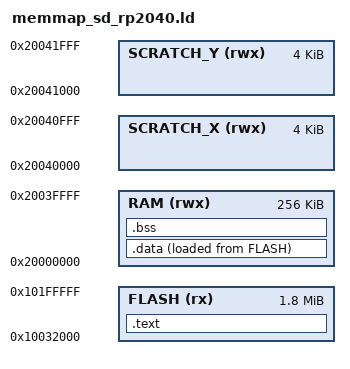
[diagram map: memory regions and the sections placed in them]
MEMORY
{
    FLASH(rx) : ORIGIN = 0x10000000 + 200k, LENGTH = 2048k - 200k
    RAM(rwx) : ORIGIN = 0x20000000, LENGTH = 256k
    SCRATCH_X(rwx) : ORIGIN = 0x20040000, LENGTH = 4k
    SCRATCH_Y(rwx) : ORIGIN = 0x20041000, LENGTH = 4k
}

ENTRY(bare_reset)

SECTIONS
{
    .text : {
        __text_start = .;
        KEEP(*(.vectors))
        *(.text*)
        *(.rodata*)
        . = ALIGN(4);
        __text_end = .;
    } > FLASH

    .data : {
        . = ALIGN(4);
        __data_start = .;
        *(.data*)
        . = ALIGN(4);
        __data_end = .;
    } > RAM AT > FLASH
    __data_source = LOADADDR(.data);

    .bss (NOLOAD) : {
        . = ALIGN(4);
        __bss_start = .;
        *(.bss*)
        *(COMMON)
        . = ALIGN(4);
        __bss_end = .;
    } > RAM

    __StackTop = ORIGIN(SCRATCH_Y) + LENGTH(SCRATCH_Y);
    PROVIDE(__stack = __StackTop);
}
